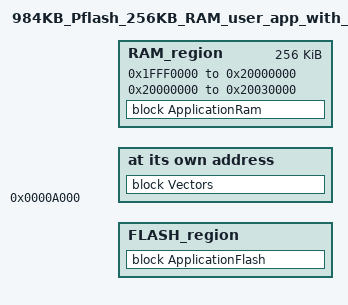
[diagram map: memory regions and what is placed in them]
/*###ICF### Section handled by ICF editor, don't touch! ****/
/*-Editor annotation file-*/
/* IcfEditorFile="$TOOLKIT_DIR$\config\ide\IcfEditor\cortex_v1_0.xml" */
/*-Memory Regions-*/
define symbol __ICFEDIT_region_FLASH_start__ = 0xa000;       // User application space after bootloader
define symbol __ICFEDIT_region_FLASH_end__   = (1024*1024);
define symbol __ICFEDIT_region_RAM_end__     = 0x20000000;
define symbol __ICFEDIT_region_RAM_start__   = __ICFEDIT_region_RAM_end__ - (256*1024)/4;
/*-Specials-*/
define symbol __ICFEDIT_intvec_start__ = __ICFEDIT_region_FLASH_start__;

/*-Sizes-*/
define symbol __ICFEDIT_size_cstack__ = (1*1024); //********
define symbol __ICFEDIT_size_heap__   = (2*1024); //********
/**** End of ICF editor section. ###ICF###*/

define symbol __region_RAM2_start__        = 0x20000000;
define symbol __region_RAM2_end__          = __region_RAM2_start__ + ((256*1024)*3)/4;

define exported symbol __VECTOR_TABLE      = __ICFEDIT_region_FLASH_start__;
define exported symbol __VECTOR_RAM        = __ICFEDIT_region_RAM_start__;

define exported symbol __BOOT_STACK_ADDRESS = __region_RAM2_end__ - 8;

define memory mem with size = 4G;
define region FLASH_region = mem:[from __ICFEDIT_region_FLASH_start__ to __ICFEDIT_region_FLASH_end__];
define region RAM_region   = mem:[from __ICFEDIT_region_RAM_start__   to __ICFEDIT_region_RAM_end__] | mem:[from __region_RAM2_start__ to __region_RAM2_end__];

define block CSTACK    with alignment = 8, size = __ICFEDIT_size_cstack__   { };
define block HEAP      with alignment = 8, size = __ICFEDIT_size_heap__     { };

initialize manually { readwrite };
initialize manually { section .data};
initialize manually { section .textrw };
do not initialize  { section .noinit };


define block Vectors with alignment=256 { readonly section .intvec };
define block CodeRelocate { section .textrw_init };
define block CodeRelocateRam { section .textrw };
place at address mem:__ICFEDIT_intvec_start__ { block Vectors };

define block ApplicationFlash { readonly section .noinit, readonly, block CodeRelocate };
place in FLASH_region   { block ApplicationFlash };

define block ApplicationRam { readwrite, block CodeRelocateRam, block CSTACK, block HEAP };
place in RAM_region   { block ApplicationRam };
